# SAM9X60 device description
Architecture: ARM926EJS; Family: SAM9; Series: SAM9X
Registers are 32-bit, read-write, no defined reset value unless marked. A register's access mark holds for its fields unless they carry their own. Offsets are from the block's base; [hi:lo] are bit positions; {n}, {i} and the like mark numbered series.

## I2SMCC — Inter-IC Sound Multi Channel Controller
Instances: I2SMCC 0xF001C000
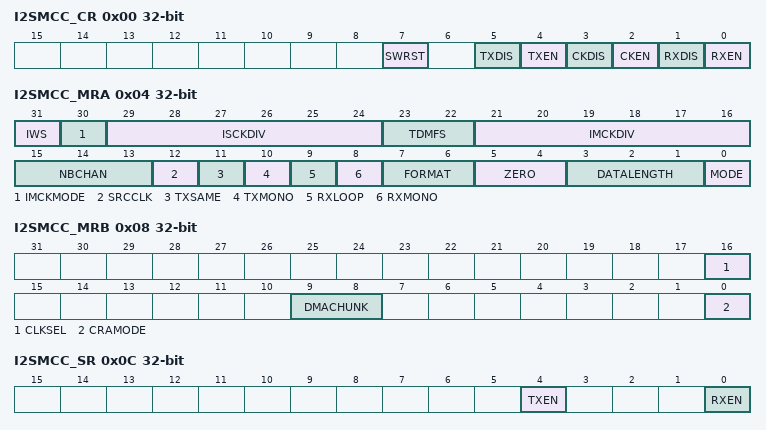
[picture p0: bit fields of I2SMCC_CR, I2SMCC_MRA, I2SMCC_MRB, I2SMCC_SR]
0x00 I2SMCC_CR wo — Control Register
  [7] SWRST — Software Reset
  [5] TXDIS — Transmitter Disable
  [4] TXEN — Transmitter Enable
  [3] CKDIS — Clocks Disable
  [2] CKEN — Clocks Enable
  [1] RXDIS — Receiver Disable
  [0] RXEN — Receiver Enable
0x04 I2SMCC_MRA — Mode Register A
  [31] IWS — I2SMCC_WS Slot Length
  [30] IMCKMODE — Master Clock Mode
  [29:24] ISCKDIV — Selected Clock to I2SMCC Serial Clock Ratio
  [23:22] TDMFS — TDM Frame Synchronization
    0=SLOT (I2SMCC_WS pulse is high for one time slot at beginning of frame.); 1=HALF (I2SMCC_WS pulse is high for half the time slots at beginning of frame.); 2=BIT (I2SMCC_WS pulse is high for one bit period at beginning of frame, i.e., one ISCK period.)
  [21:16] IMCKDIV — Selected Clock to I2SMCC Master Clock Ratio
  [15:13] NBCHAN — Number of TDM Channels-1
  [12] SRCCLK — Source Clock Selection
  [11] TXSAME — Transmit Data when Underrun
  [10] TXMONO — Transmit Mono
  [9] RXLOOP — Loop-back Test Mode
  [8] RXMONO — Receive Mono
  [7:6] FORMAT — Data Format
    0=I2S (I2S format, stereo with I2SMCC_WS low for left channel, and MSB of sample starting one I2SMCC_CK period after I2SMCC_WS edge.); 1=LJ (Left-justified format, stereo with I2SMCC_WS high for left channel, and MSB of sample starting on I2SMCC_WS edge.); 2=TDM (TDM format, with (NBCHAN + 1) channels, I2SMCC_WS high at beginning of first channel, and MSB of sample starting one I2SMCC_CK period after I2SMCC_WS edge.); 3=TDMLJ (TDM format, left-justified, with (NBCHAN + 1) channels, I2SMCC_WS high at beginning of first channel, and MSB of sample starting on I2SMCC_WS edge.)
  [5:4] ZERO — This field must always be written to 0.
  [3:1] DATALENGTH — Data Word Length
    0=_32_BITS (Data length is set to 32 bits.); 1=_24_BITS (Data length is set to 24 bits.); 2=_20_BITS (Data length is set to 20 bits.); 3=_18_BITS (Data length is set to 18 bits.); 4=_16_BITS (Data length is set to 16 bits.); 5=_16_BITS_COMPACT (Data length is set to 16-bit compact stereo. Left sample in bits [15:0] and right sample in bits [31:16] of same word.); 6=_8_BITS (Data length is set to 8 bits.); 7=_8_BITS_COMPACT (Data length is set to 8-bit compact stereo. Left sample in bits [7:0] and right sample in bits [15:8] of the same word.)
  [0] MODE — Inter-IC Sound Multi Channel Controller Mode
    0=SLAVE (I2SMCC_CK and I2SMCC_WS pin inputs used as bit clock and word select/frame synchronization.); 1=MASTER (Bit clock and word select/frame synchronization generated by I2SMCC from MCK and output to I2SMCC_CK and I2SMCC_WS pins. MCK is output as master clock on I2SMCC_MCK if I2SMCC_MRA.IMCKMODE is set.)
0x08 I2SMCC_MRB — Mode Register B
  [16] CLKSEL — Serial Clock Selection
  [9:8] DMACHUNK — DMA Chunk Size
    0=_1_WORD (Each DMA transfer contains 1 word.); 1=_2_WORDS (Each DMA transfer contains 2 words.); 2=_4_WORDS (Each DMA transfer contains 4 words.); 3=_8_WORDS (Each DMA transfer contains 8 words.)
  [0] CRAMODE — Common Register Access Mode
    0=LEFT_FIRST (All enabled I2S left channels are filled first, then I2S right channels.); 1=REGULAR (An enabled I2S left channel is filled, then the corresponding right channel, until all channels are filled.)
0x0C I2SMCC_SR ro — Status Register
  [4] TXEN — Transmitter Enabled
  [0] RXEN — Receiver Enabled
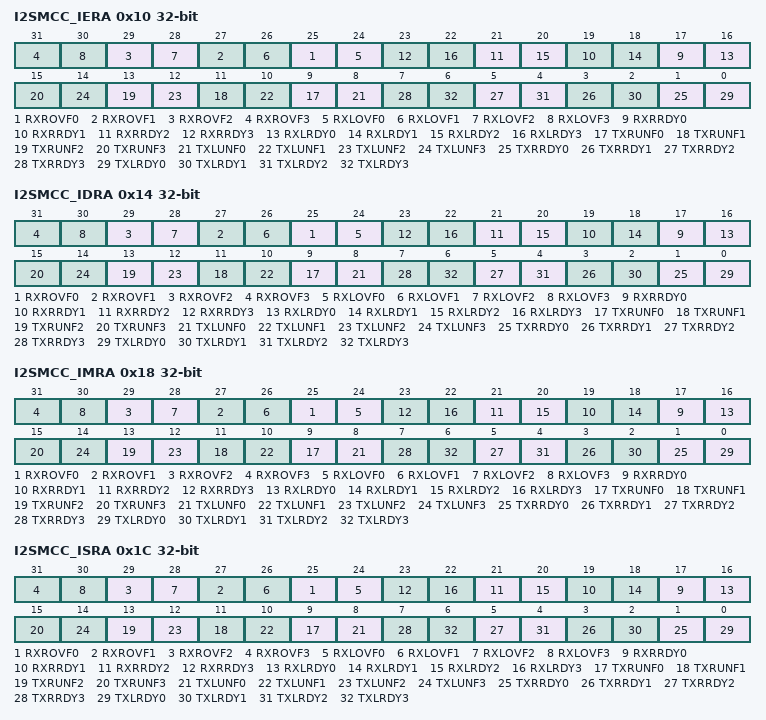
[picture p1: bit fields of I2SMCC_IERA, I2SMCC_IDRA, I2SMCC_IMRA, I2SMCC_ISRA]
0x10 I2SMCC_IERA wo — Interrupt Enable Register A
  [2n+25] RXROVF{n} (n=0..3) — I2S Receive Right {n} (x=0 only) or TDM Channel [2x]+1 Overrun Interrupt Enable
  [2n+24] RXLOVF{n} (n=0..3) — I2S Receive Left {n} (x=0 only) or TDM Channel 2x Overrun Interrupt Enable
  [2n+17] RXRRDY{n} (n=0..3) — I2S Receive Right {n} (x=0 only) or TDM Channel [2x]+1 Ready Interrupt Enable
  [2n+16] RXLRDY{n} (n=0..3) — I2S Receive Left {n} (x=0 only) or TDM Channel 2x Ready Interrupt Enable
  [2n+9] TXRUNF{n} (n=0..3) — I2S Transmit Right {n} (x=0 only) or TDM Channel [2x]+1 Underrun Interrupt Enable
  [2n+8] TXLUNF{n} (n=0..3) — I2S Transmit Left {n} (x=0 only) or TDM Channel 2x Underrun Interrupt Enable
  [2n+1] TXRRDY{n} (n=0..3) — I2S Transmit Right {n} (x=0 only) or TDM Channel [2x]+1 Ready Interrupt Enable
  [2n] TXLRDY{n} (n=0..3) — I2S Transmit Left {n} (x=0 only) or TDM Channel 2x Ready Interrupt Enable
0x14 I2SMCC_IDRA wo — Interrupt Disable Register A
  [2n+25] RXROVF{n} (n=0..3) — I2S Receive Right {n} (x=0 only) or TDM Channel [2x]+1 Overrun Interrupt Disable
  [2n+24] RXLOVF{n} (n=0..3) — I2S Receive Left {n} (x=0 only) or TDM Channel 2x Overrun Interrupt Disable
  [2n+17] RXRRDY{n} (n=0..3) — I2S Receive Right {n} (x=0 only) or TDM Channel [2x]+1 Ready Interrupt Disable
  [2n+16] RXLRDY{n} (n=0..3) — I2S Receive Left {n} (x=0 only) or TDM Channel 2x Ready Interrupt Disable
  [2n+9] TXRUNF{n} (n=0..3) — I2S Transmit Right {n} (x=0 only) or TDM Channel [2x]+1 Underrun Interrupt Disable
  [2n+8] TXLUNF{n} (n=0..3) — I2S Transmit Left {n} (x=0 only) or TDM Channel 2x Underrun Interrupt Disable
  [2n+1] TXRRDY{n} (n=0..3) — I2S Transmit Right {n} (x=0 only) or TDM Channel [2x]+1 Ready Interrupt Disable
  [2n] TXLRDY{n} (n=0..3) — I2S Transmit Left {n} (x=0 only) or TDM Channel 2x Ready Interrupt Disable
0x18 I2SMCC_IMRA ro — Interrupt Mask Register A
  [2n+25] RXROVF{n} (n=0..3) — I2S Receive Right {n} (x=0 only) or TDM Channel [2x]+1 Overrun Interrupt Mask
  [2n+24] RXLOVF{n} (n=0..3) — I2S Receive Left {n} (x=0 only) or TDM Channel 2x Overrun Interrupt Mask
  [2n+17] RXRRDY{n} (n=0..3) — I2S Receive Right {n} (x=0 only) or TDM Channel [2x]+1 Ready Interrupt Mask
  [2n+16] RXLRDY{n} (n=0..3) — I2S Receive Left {n} (x=0 only) or TDM Channel 2x Ready Interrupt Mask
  [2n+9] TXRUNF{n} (n=0..3) — I2S Transmit Right {n} (x=0 only) or TDM Channel [2x]+1 Underrun Interrupt Mask
  [2n+8] TXLUNF{n} (n=0..3) — I2S Transmit Left {n} (x=0 only) or TDM Channel 2x Underrun Interrupt Mask
  [2n+1] TXRRDY{n} (n=0..3) — I2S Transmit Right {n} (x=0 only) or TDM Channel [2x]+1 Ready Interrupt Mask
  [2n] TXLRDY{n} (n=0..3) — I2S Transmit Left {n} (x=0 only) or TDM Channel 2x Ready Interrupt Mask
0x1C I2SMCC_ISRA ro — Interrupt Status Register A
  [2n+25] RXROVF{n} (n=0..3) — I2S Receive Right {n} (x=0 only) or TDM Channel [2x]+1 Overrun Flag (Cleared on read)
  [2n+24] RXLOVF{n} (n=0..3) — I2S Receive Left {n} (x=0 only) or TDM Channel 2x Overrun Flag (Cleared on read)
  [2n+17] RXRRDY{n} (n=0..3) — I2S Receive Right {n} (x=0 only) or TDM Channel [2x]+1 Ready Flag (Cleared by reading I2SMCC_RHR)
  [2n+16] RXLRDY{n} (n=0..3) — I2S Receive Left {n} (x=0 only) or TDM Channel 2x Ready Flag (Cleared by reading I2SMCC_RHR)
  [2n+9] TXRUNF{n} (n=0..3) — I2S Transmit Right {n} (x=0 only) or TDM Channel [2x]+1 Underrun Flag (Cleared on read)
  [2n+8] TXLUNF{n} (n=0..3) — I2S Transmit Left {n} (x=0 only) or TDM Channel 2x Underrun (Cleared on read)
  [2n+1] TXRRDY{n} (n=0..3) — I2S Transmit Right {n} (x=0 only) or TDM Channel [2x]+1 Ready Flag (Cleared by writing I2SMCC_THR)
  [2n] TXLRDY{n} (n=0..3) — I2S Transmit Left {n} (x=0 only) or TDM Channel 2x Ready Flag (Cleared by writing I2SMCC_THR)
0x20 I2SMCC_IERB wo — Interrupt Enable Register B
  [0] WERR — Write Error Interrupt Enable
0x24 I2SMCC_IDRB wo — Interrupt Disable Register B
  [0] WERR — Write Error Interrupt Disable
0x28 I2SMCC_IMRB ro — Interrupt Mask Register B
  [0] WERR — Write Error Interrupt Mask
0x2C I2SMCC_ISRB ro — Interrupt Status Register B
  [0] WERR — Write Error Flag (Cleared on read)
0x30 I2SMCC_RHR ro — Receiver Holding Register
0x34 I2SMCC_THR wo — Transmitter Holding Register
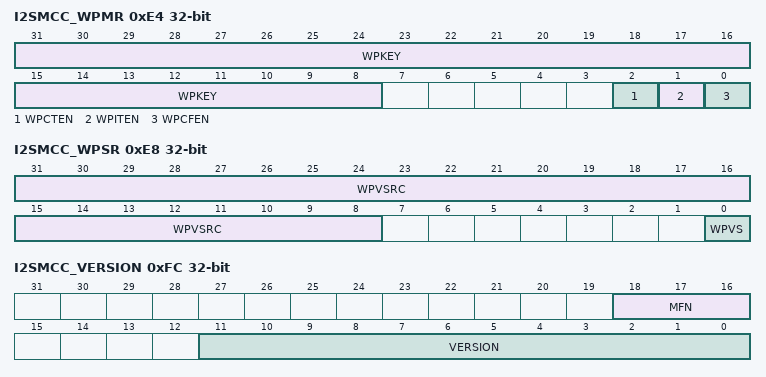
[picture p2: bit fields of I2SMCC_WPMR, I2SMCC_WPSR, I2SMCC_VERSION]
0xE4 I2SMCC_WPMR — Write Protection Mode Register
  [31:8] WPKEY — Write Protection Key
    0x493253=PASSWD (Writing any other value in this field aborts the write operation. Always reads as 0.)
  [2] WPCTEN — Write Protection Control Enable
  [1] WPITEN — Write Protection Interrupt Enable
  [0] WPCFEN — Write Protection Configuration Enable
0xE8 I2SMCC_WPSR ro — Write Protection Status Register
  [31:8] WPVSRC — Write Protection Violation Source
  [0] WPVS — Write Protection Violation Status
0xFC I2SMCC_VERSION ro — Version Register
  [18:16] MFN — Metal Fix Number
  [11:0] VERSION — Version of the Hardware Module
